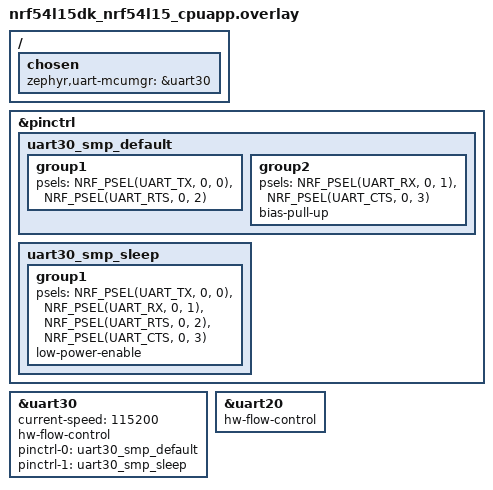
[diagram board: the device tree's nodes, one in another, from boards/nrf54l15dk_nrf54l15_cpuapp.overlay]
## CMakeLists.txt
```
#
# Copyright (c) 2026 Nordic Semiconductor
#
# SPDX-License-Identifier: LicenseRef-Nordic-5-Clause
#

cmake_minimum_required(VERSION 3.20.0)

find_package(Zephyr REQUIRED HINTS $ENV{ZEPHYR_BASE})
project(sm_fota_smp_srv)

target_sources(app PRIVATE src/main.c)
```

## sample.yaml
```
sample:
  name: Serial Modem SMP server
tests:
  serial_modem.sm_fota_smp_srv:
    build_only: true
    integration_platforms:
      - nrf54l15dk/nrf54l15/cpuapp
    platform_allow: nrf54l15dk/nrf54l15/cpuapp
    tags:
      - ci_build
```

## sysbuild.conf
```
# Copyright (c) 2026 Nordic Semiconductor ASA
# SPDX-License-Identifier: LicenseRef-Nordic-5-Clause

SB_CONFIG_BOOTLOADER_MCUBOOT=n
```

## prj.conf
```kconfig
# Copyright (c) 2026 Nordic Semiconductor ASA
# SPDX-License-Identifier: LicenseRef-Nordic-5-Clause

CONFIG_MAIN_STACK_SIZE=2048
CONFIG_SYSTEM_WORKQUEUE_STACK_SIZE=2304

CONFIG_LOG=y
CONFIG_LOG_DEFAULT_LEVEL=3
CONFIG_CONSOLE=y

# Console/logs over SEGGER RTT (VCOM is freed for the SMP UART link).
CONFIG_UART_CONSOLE=n
CONFIG_LOG_BACKEND_UART=n
CONFIG_USE_SEGGER_RTT=y
CONFIG_RTT_CONSOLE=y
CONFIG_LOG_BACKEND_RTT=y

CONFIG_NET_BUF=y
CONFIG_ZCBOR=y
CONFIG_ZCBOR_CANONICAL=y
CONFIG_CRC=y
CONFIG_MCUMGR=y

CONFIG_BASE64=y
CONFIG_UART_MCUMGR=y
CONFIG_MCUMGR_TRANSPORT_UART=y

# Built-in OS-group echo handler answers the nRF9151 client's
# os_mgmt_client_echo() round-trip test (it is byte-for-byte compatible with
# the client encoder, unlike a hand-rolled handler).
CONFIG_MCUMGR_GRP_OS=y
CONFIG_MCUMGR_GRP_OS_ECHO=y
CONFIG_MCUMGR_GRP_OS_TASKSTAT=n
CONFIG_MCUMGR_GRP_OS_MPSTAT=n

# Notification hooks: emit MGMT_EVT_OP_CMD_RECV when an SMP command arrives so
# src/main.c can LOG on the server side that the echo round-trip reached it.
CONFIG_MCUMGR_MGMT_NOTIFICATION_HOOKS=y
CONFIG_MCUMGR_SMP_COMMAND_STATUS_HOOKS=y
```

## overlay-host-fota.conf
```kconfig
CONFIG_MEMFAULT_FOTA_MODEM_UPDATE=y
CONFIG_MEMFAULT_FOTA_MODEM_SOFTWARE_TYPE="host"

# Update with a new project key, see https://docs.memfault.com/docs/mcu/nrf-modem-fota
CONFIG_MEMFAULT_FOTA_MODEM_PROJECT_KEY="YOUR_PROJECT_KEY"
```

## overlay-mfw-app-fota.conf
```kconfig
CONFIG_MEMFAULT_FOTA_MODEM_UPDATE=y
CONFIG_MEMFAULT_FOTA_MODEM_SOFTWARE_TYPE="mfw-app"

# Update with a new project key, see https://docs.memfault.com/docs/mcu/nrf-modem-fota
CONFIG_MEMFAULT_FOTA_MODEM_PROJECT_KEY="YOUR_PROJECT_KEY"
```

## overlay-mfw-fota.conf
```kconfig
CONFIG_MEMFAULT_FOTA_MODEM_UPDATE=y

# Update with a new project key, see https://docs.memfault.com/docs/mcu/nrf-modem-fota
CONFIG_MEMFAULT_FOTA_MODEM_PROJECT_KEY="YOUR_PROJECT_KEY"
```

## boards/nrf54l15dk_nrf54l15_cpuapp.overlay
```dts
/*
 * Copyright (c) 2026 Nordic Semiconductor ASA
 *
 * SPDX-License-Identifier: LicenseRef-Nordic-5-Clause
 */

/ {
	chosen {
		/* SMP transport. Console/logs go over SEGGER RTT (see prj.conf), so
		 * no zephyr,console/shell-uart here — that keeps uart20 (P1.04-07)
		 * free for the future AT host link.
		 */
		zephyr,uart-mcumgr = &uart30;
	};
};

&pinctrl {
	uart30_smp_default: uart30_smp_default {
		group1 {
			psels = <NRF_PSEL(UART_TX, 0, 0)>,
				<NRF_PSEL(UART_RTS, 0, 2)>;
		};

		group2 {
			psels = <NRF_PSEL(UART_RX, 0, 1)>,
				<NRF_PSEL(UART_CTS, 0, 3)>;
			bias-pull-up;
		};
	};

	uart30_smp_sleep: uart30_smp_sleep {
		group1 {
			psels = <NRF_PSEL(UART_TX, 0, 0)>,
				<NRF_PSEL(UART_RX, 0, 1)>,
				<NRF_PSEL(UART_RTS, 0, 2)>,
				<NRF_PSEL(UART_CTS, 0, 3)>;
			low-power-enable;
		};
	};
};

&uart30 {
	status = "okay";
	current-speed = <115200>;
	hw-flow-control;
	pinctrl-0 = <&uart30_smp_default>;
	pinctrl-1 = <&uart30_smp_sleep>;
	pinctrl-names = "default", "sleep";
};

/* Console moved to RTT (see prj.conf), so uart20 (P1.04-07) is repurposed as the
 * AT host link: the L15 drives the nRF9151's serial_modem AT interface (its uart0).
 * Wiring (crossover): L15 P1.04 TX -> 9151 P0.26 RX, P1.05 RX <- P0.27 TX,
 * P1.06 RTS -> P0.15 CTS, P1.07 CTS <- P0.14 RTS. 115200 + HW flow control to
 * match the nRF9151 uart0 AT host. pinctrl/speed inherited from the board dtsi.
 */
&uart20 {
	status = "okay";
	hw-flow-control;
};
```

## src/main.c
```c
/*
 * Copyright (c) 2026 Nordic Semiconductor ASA
 *
 * SPDX-License-Identifier: LicenseRef-Nordic-5-Clause
 */

#include <zephyr/kernel.h>
#include <zephyr/logging/log.h>
#include <zephyr/device.h>
#include <zephyr/drivers/uart.h>
#include <string.h>
#include <zephyr/mgmt/mcumgr/mgmt/callbacks.h>
#include <zephyr/mgmt/mcumgr/mgmt/mgmt.h>
#include <zephyr/mgmt/mcumgr/grp/os_mgmt/os_mgmt.h>

LOG_MODULE_REGISTER(sm_fota_smp_srv, CONFIG_LOG_DEFAULT_LEVEL);

/*
 * AT-host link: uart20 (P1.04-07) is wired to the nRF9151's serial_modem AT
 * interface (its uart0). The L15 acts as the AT host that drives the modem.
 * serial_modem uses CR ('\r') command termination by default.
 */
static const struct device *const at_uart = DEVICE_DT_GET(DT_NODELABEL(uart20));

static void at_host_send(const char *cmd)
{
	LOG_INF("AT-host TX -> nRF9151: \"%s\"", cmd);
	for (const char *p = cmd; *p != '\0'; p++) {
		uart_poll_out(at_uart, (unsigned char)*p);
	}
	uart_poll_out(at_uart, '\r');
}

static void at_host_read_response(uint32_t window_ms)
{
	uint8_t buf[256];
	size_t len = 0U;
	int64_t deadline = k_uptime_get() + window_ms;
	unsigned char c;

	while (k_uptime_get() < deadline && len < (sizeof(buf) - 1U)) {
		if (uart_poll_in(at_uart, &c) == 0) {
			buf[len++] = c;
		} else {
			k_sleep(K_MSEC(2));
		}
	}
	buf[len] = '\0';

	if (len == 0U) {
		LOG_WRN("AT-host RX <- nRF9151: nothing within %u ms", window_ms);
		return;
	}

	LOG_INF("AT-host RX <- nRF9151: %u bytes", (unsigned int)len);
	LOG_HEXDUMP_INF(buf, len, "raw response");
	if (strstr((char *)buf, "OK") != NULL) {
		LOG_INF("AT-host: got OK from nRF9151 -- L15->9151 AT link works!");
	} else {
		LOG_WRN("AT-host: response received but no \"OK\" found");
	}
}

static void at_host_test(void)
{
	if (!device_is_ready(at_uart)) {
		LOG_ERR("AT-host UART (uart20) not ready");
		return;
	}

	/* Let the nRF9151 serial_modem finish bringing up its AT host. */
	k_sleep(K_SECONDS(3));
	at_host_send("AT");
	at_host_read_response(2000U);
}

/*
 * The actual OS-group echo is serviced by the built-in mcumgr handler
 * (CONFIG_MCUMGR_GRP_OS_ECHO), which is byte-for-byte compatible with the
 * nRF9151 client's os_mgmt_client_echo(). We only hook the generic
 * "command received" notification so the server can LOG on its own console
 * that the round-trip reached it -- that on-server log is the proof the
 * client's echo physically arrived and was dispatched.
 */
static enum mgmt_cb_return smp_cmd_recv_cb(uint32_t event, enum mgmt_cb_return prev_status,
					   int32_t *rc, uint16_t *group, bool *abort_more,
					   void *data, size_t data_size)
{
	if (event == MGMT_EVT_OP_CMD_RECV && data != NULL &&
	    data_size >= sizeof(struct mgmt_evt_op_cmd_arg)) {
		const struct mgmt_evt_op_cmd_arg *arg = data;

		if (arg->group == MGMT_GROUP_ID_OS && arg->id == OS_MGMT_ID_ECHO) {
			LOG_INF("SMP echo received from client (OS group, echo command)");
		} else {
			LOG_INF("SMP command received: group=%u id=%u", arg->group, arg->id);
		}
	}

	return MGMT_CB_OK;
}

static struct mgmt_callback smp_cmd_recv_callback = {
	.callback = smp_cmd_recv_cb,
	.event_id = MGMT_EVT_OP_CMD_RECV,
};

int main(void)
{
	mgmt_callback_register(&smp_cmd_recv_callback);

	LOG_INF("SMP server ready");

	at_host_test();

	while (true) {
		k_sleep(K_FOREVER);
	}

	return 0;
}
```
